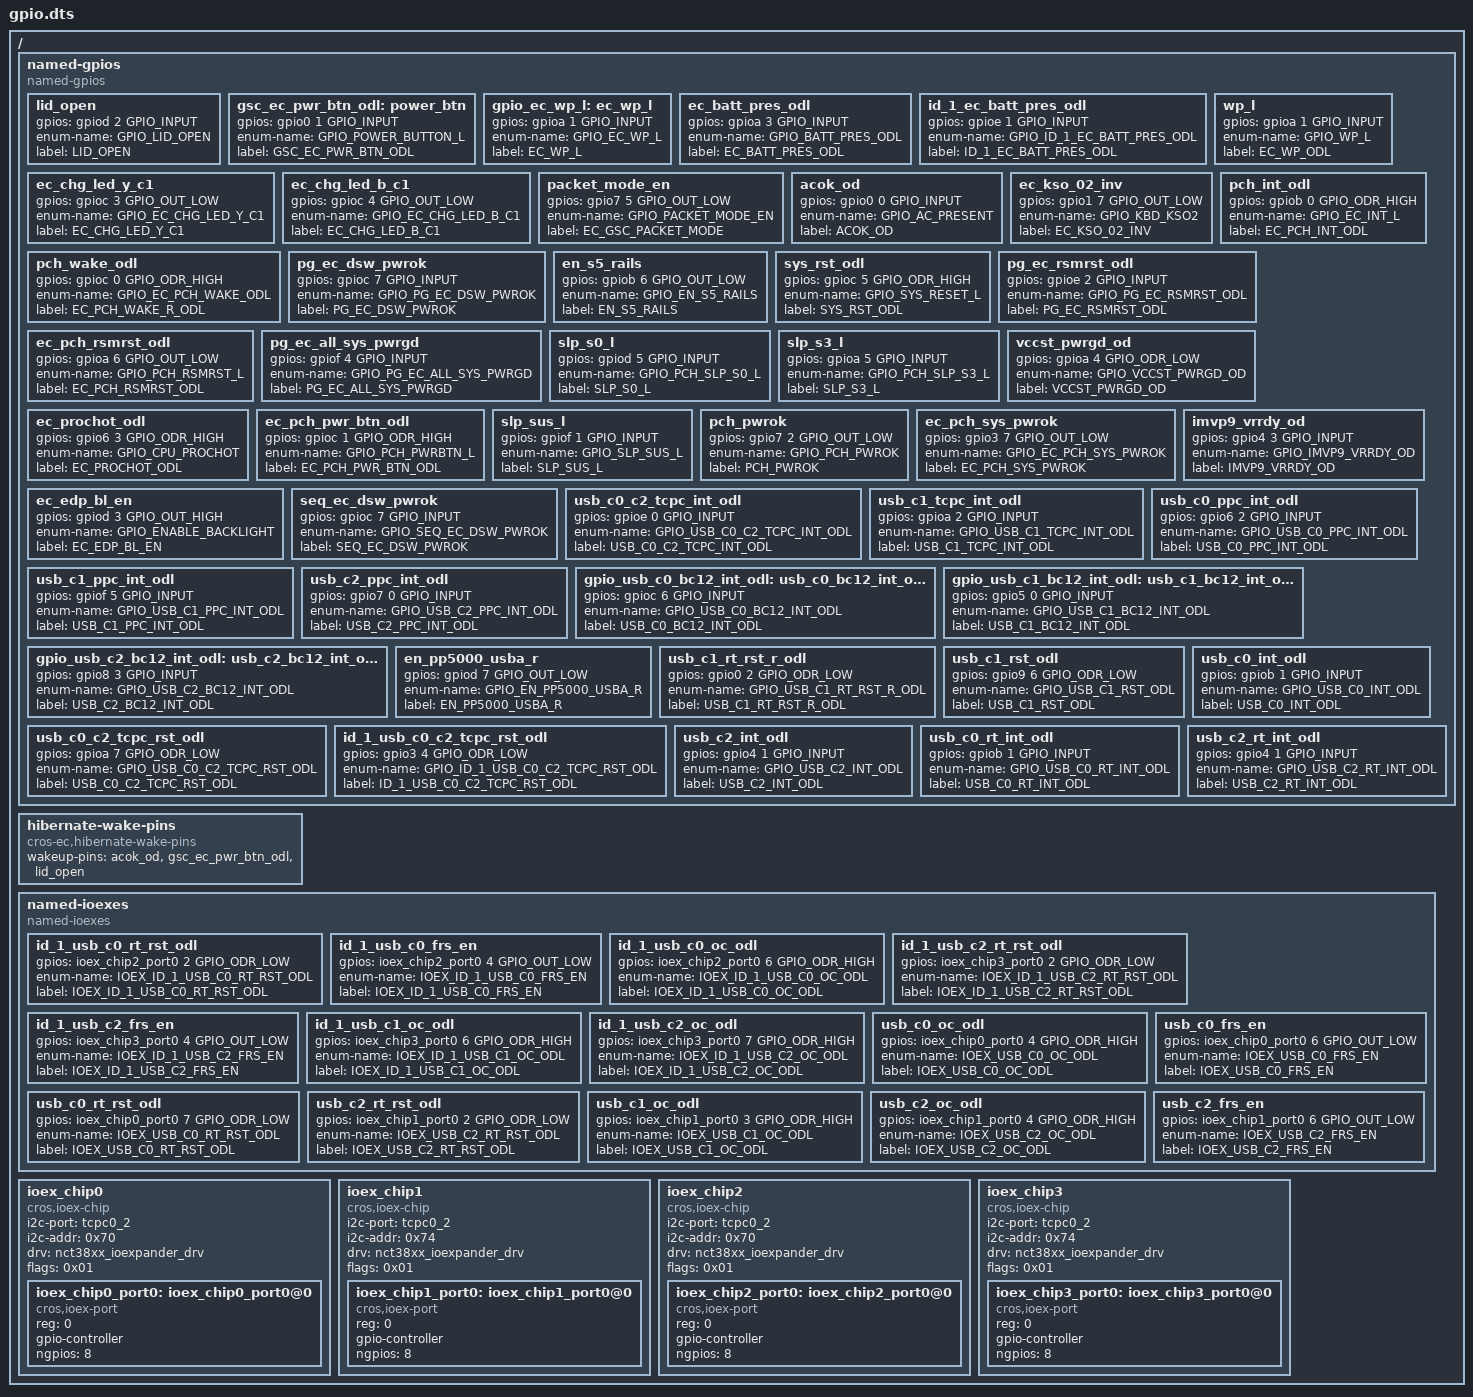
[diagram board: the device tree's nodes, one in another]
/* Copyright 2021 The Chromium OS Authors. All rights reserved.
 * Use of this source code is governed by a BSD-style license that can be
 * found in the LICENSE file.
 */

/ {
	named-gpios {
		compatible = "named-gpios";

		lid_open: lid_open {
			gpios = <&gpiod 2 GPIO_INPUT>;
			enum-name = "GPIO_LID_OPEN";
			label = "LID_OPEN";
		};

		gsc_ec_pwr_btn_odl: power_btn {
			gpios = <&gpio0 1 GPIO_INPUT>;
			enum-name = "GPIO_POWER_BUTTON_L";
			label = "GSC_EC_PWR_BTN_ODL";
		};

		gpio_ec_wp_l: ec_wp_l {
			#gpio-cells = <0>;
			gpios = <&gpioa 1 GPIO_INPUT>;
			enum-name = "GPIO_EC_WP_L";
			label = "EC_WP_L";
		};

		ec_batt_pres_odl {
			gpios = <&gpioa 3 GPIO_INPUT>;
			enum-name = "GPIO_BATT_PRES_ODL";
			label = "EC_BATT_PRES_ODL";
		};

		id_1_ec_batt_pres_odl {
			gpios = <&gpioe 1 GPIO_INPUT>;
			enum-name = "GPIO_ID_1_EC_BATT_PRES_ODL";
			label = "ID_1_EC_BATT_PRES_ODL";
		};

		wp_l {
			gpios = <&gpioa 1 GPIO_INPUT>;
			enum-name = "GPIO_WP_L";
			label = "EC_WP_ODL";
		};

		ec_chg_led_y_c1 {
			gpios = <&gpioc 3 GPIO_OUT_LOW>;
			enum-name = "GPIO_EC_CHG_LED_Y_C1";
			label = "EC_CHG_LED_Y_C1";
		};

		ec_chg_led_b_c1 {
			gpios = <&gpioc 4 GPIO_OUT_LOW>;
			enum-name = "GPIO_EC_CHG_LED_B_C1";
			label = "EC_CHG_LED_B_C1";
		};

		packet_mode_en {
			gpios = <&gpio7 5 GPIO_OUT_LOW>;
			enum-name = "GPIO_PACKET_MODE_EN";
			label = "EC_GSC_PACKET_MODE";
		};
		acok_od: acok_od {
			gpios = <&gpio0 0 GPIO_INPUT>;
			enum-name = "GPIO_AC_PRESENT";
			label = "ACOK_OD";
		};
		ec_kso_02_inv {
			gpios = <&gpio1 7 GPIO_OUT_LOW>;
			enum-name = "GPIO_KBD_KSO2";
			label = "EC_KSO_02_INV";
		};
		pch_wake_odl {
			gpios = <&gpioc 0 GPIO_ODR_HIGH>;
			enum-name = "GPIO_EC_PCH_WAKE_ODL";
			label = "EC_PCH_WAKE_R_ODL";
		};
		pch_int_odl {
			gpios = <&gpiob 0 GPIO_ODR_HIGH>;
			enum-name = "GPIO_EC_INT_L";
			label = "EC_PCH_INT_ODL";
		};
		pg_ec_dsw_pwrok {
			gpios = <&gpioc 7 GPIO_INPUT>;
			enum-name = "GPIO_PG_EC_DSW_PWROK";
			label = "PG_EC_DSW_PWROK";
		};
		en_s5_rails {
			gpios = <&gpiob 6 GPIO_OUT_LOW>;
			enum-name = "GPIO_EN_S5_RAILS";
			label = "EN_S5_RAILS";
		};
		sys_rst_odl {
			gpios = <&gpioc 5 GPIO_ODR_HIGH>;
			enum-name = "GPIO_SYS_RESET_L";
			label = "SYS_RST_ODL";
		};
		pg_ec_rsmrst_odl {
			gpios = <&gpioe 2 GPIO_INPUT>;
			enum-name = "GPIO_PG_EC_RSMRST_ODL";
			label = "PG_EC_RSMRST_ODL";
		};
		ec_pch_rsmrst_odl {
			gpios = <&gpioa 6 GPIO_OUT_LOW>;
			enum-name = "GPIO_PCH_RSMRST_L";
			label = "EC_PCH_RSMRST_ODL";
		};
		pg_ec_all_sys_pwrgd {
			gpios = <&gpiof 4 GPIO_INPUT>;
			enum-name = "GPIO_PG_EC_ALL_SYS_PWRGD";
			label = "PG_EC_ALL_SYS_PWRGD";
		};
		slp_s0_l {
			gpios = <&gpiod 5 GPIO_INPUT>;
			enum-name = "GPIO_PCH_SLP_S0_L";
			label = "SLP_S0_L";
		};
		slp_s3_l {
			gpios = <&gpioa 5 GPIO_INPUT>;
			enum-name = "GPIO_PCH_SLP_S3_L";
			label = "SLP_S3_L";
		};
		vccst_pwrgd_od {
			gpios = <&gpioa 4 GPIO_ODR_LOW>;
			enum-name = "GPIO_VCCST_PWRGD_OD";
			label = "VCCST_PWRGD_OD";
		};
		ec_prochot_odl {
			gpios = <&gpio6 3 GPIO_ODR_HIGH>;
			enum-name = "GPIO_CPU_PROCHOT";
			label = "EC_PROCHOT_ODL";
		};
		ec_pch_pwr_btn_odl {
			gpios = <&gpioc 1 GPIO_ODR_HIGH>;
			enum-name = "GPIO_PCH_PWRBTN_L";
			label = "EC_PCH_PWR_BTN_ODL";
		};
		slp_sus_l {
			gpios = <&gpiof 1 GPIO_INPUT>;
			enum-name = "GPIO_SLP_SUS_L";
			label = "SLP_SUS_L";
		};
		pch_pwrok {
			gpios = <&gpio7 2 GPIO_OUT_LOW>;
			enum-name = "GPIO_PCH_PWROK";
			label = "PCH_PWROK";
		};
		ec_pch_sys_pwrok {
			gpios = <&gpio3 7 GPIO_OUT_LOW>;
			enum-name = "GPIO_EC_PCH_SYS_PWROK";
			label = "EC_PCH_SYS_PWROK";
		};
		imvp9_vrrdy_od {
			gpios = <&gpio4 3 GPIO_INPUT>;
			enum-name = "GPIO_IMVP9_VRRDY_OD";
			label = "IMVP9_VRRDY_OD";
		};
		ec_edp_bl_en {
			gpios = <&gpiod 3 GPIO_OUT_HIGH>;
			enum-name = "GPIO_ENABLE_BACKLIGHT";
			label = "EC_EDP_BL_EN";
		};
		seq_ec_dsw_pwrok {
			gpios = <&gpioc 7 GPIO_INPUT>;
			enum-name = "GPIO_SEQ_EC_DSW_PWROK";
			label = "SEQ_EC_DSW_PWROK";
		};
		usb_c0_c2_tcpc_int_odl {
			gpios = <&gpioe 0 GPIO_INPUT>;
			enum-name = "GPIO_USB_C0_C2_TCPC_INT_ODL";
			label = "USB_C0_C2_TCPC_INT_ODL";
		};
		usb_c1_tcpc_int_odl {
			gpios = <&gpioa 2 GPIO_INPUT>;
			enum-name = "GPIO_USB_C1_TCPC_INT_ODL";
			label = "USB_C1_TCPC_INT_ODL";
		};
		usb_c0_ppc_int_odl {
			gpios = <&gpio6 2 GPIO_INPUT>;
			enum-name = "GPIO_USB_C0_PPC_INT_ODL";
			label = "USB_C0_PPC_INT_ODL";
		};
		usb_c1_ppc_int_odl {
			gpios = <&gpiof 5 GPIO_INPUT>;
			enum-name = "GPIO_USB_C1_PPC_INT_ODL";
			label = "USB_C1_PPC_INT_ODL";
		};
		usb_c2_ppc_int_odl {
			gpios = <&gpio7 0 GPIO_INPUT>;
			enum-name = "GPIO_USB_C2_PPC_INT_ODL";
			label = "USB_C2_PPC_INT_ODL";
		};
		gpio_usb_c0_bc12_int_odl: usb_c0_bc12_int_odl {
			gpios = <&gpioc 6 GPIO_INPUT>;
			enum-name = "GPIO_USB_C0_BC12_INT_ODL";
			label = "USB_C0_BC12_INT_ODL";
		};
		gpio_usb_c1_bc12_int_odl: usb_c1_bc12_int_odl {
			gpios = <&gpio5 0 GPIO_INPUT>;
			enum-name = "GPIO_USB_C1_BC12_INT_ODL";
			label = "USB_C1_BC12_INT_ODL";
		};
		gpio_usb_c2_bc12_int_odl: usb_c2_bc12_int_odl {
			gpios = <&gpio8 3 GPIO_INPUT>;
			enum-name = "GPIO_USB_C2_BC12_INT_ODL";
			label = "USB_C2_BC12_INT_ODL";
		};
		en_pp5000_usba_r {
			gpios = <&gpiod 7 GPIO_OUT_LOW>;
			enum-name = "GPIO_EN_PP5000_USBA_R";
			label = "EN_PP5000_USBA_R";
		};
		usb_c1_rt_rst_r_odl {
			gpios = <&gpio0 2 GPIO_ODR_LOW>;
			enum-name = "GPIO_USB_C1_RT_RST_R_ODL";
			label = "USB_C1_RT_RST_R_ODL";
		};
		usb_c1_rst_odl {
			gpios = <&gpio9 6 GPIO_ODR_LOW>;
			enum-name = "GPIO_USB_C1_RST_ODL";
			label = "USB_C1_RST_ODL";
		};
		usb_c0_c2_tcpc_rst_odl {
			gpios = <&gpioa 7 GPIO_ODR_LOW>;
			enum-name = "GPIO_USB_C0_C2_TCPC_RST_ODL";
			label = "USB_C0_C2_TCPC_RST_ODL";
		};
		id_1_usb_c0_c2_tcpc_rst_odl {
			gpios = <&gpio3 4 GPIO_ODR_LOW>;
			enum-name = "GPIO_ID_1_USB_C0_C2_TCPC_RST_ODL";
			label = "ID_1_USB_C0_C2_TCPC_RST_ODL";
		};
		usb_c0_int_odl {
			gpios = <&gpiob 1 GPIO_INPUT>;
			enum-name = "GPIO_USB_C0_INT_ODL";
			label = "USB_C0_INT_ODL";
		};
		usb_c2_int_odl {
			gpios = <&gpio4 1 GPIO_INPUT>;
			enum-name = "GPIO_USB_C2_INT_ODL";
			label = "USB_C2_INT_ODL";
		};
		usb_c0_rt_int_odl: usb_c0_rt_int_odl {
			#gpio-cells = <0>;
			gpios = <&gpiob 1 GPIO_INPUT>;
			enum-name = "GPIO_USB_C0_RT_INT_ODL";
			label = "USB_C0_RT_INT_ODL";
		};
		usb_c2_rt_int_odl: usb_c2_rt_int_odl {
			#gpio-cells = <0>;
			gpios = <&gpio4 1 GPIO_INPUT>;
			enum-name = "GPIO_USB_C2_RT_INT_ODL";
			label = "USB_C2_RT_INT_ODL";
		};
	};

	hibernate-wake-pins {
		compatible = "cros-ec,hibernate-wake-pins";
		wakeup-pins = <
			&acok_od
			&gsc_ec_pwr_btn_odl
			&lid_open
		>;
	};

	named-ioexes {
		compatible = "named-ioexes";

		id_1_usb_c0_rt_rst_odl {
			gpios = <&ioex_chip2_port0 2 GPIO_ODR_LOW>;
			enum-name = "IOEX_ID_1_USB_C0_RT_RST_ODL";
			label = "IOEX_ID_1_USB_C0_RT_RST_ODL";
		};
		id_1_usb_c0_frs_en {
			gpios = <&ioex_chip2_port0 4 GPIO_OUT_LOW>;
			enum-name = "IOEX_ID_1_USB_C0_FRS_EN";
			label = "IOEX_ID_1_USB_C0_FRS_EN";
		};
		id_1_usb_c0_oc_odl {
			gpios = <&ioex_chip2_port0 6 GPIO_ODR_HIGH>;
			enum-name = "IOEX_ID_1_USB_C0_OC_ODL";
			label = "IOEX_ID_1_USB_C0_OC_ODL";
		};
		id_1_usb_c2_rt_rst_odl {
			gpios = <&ioex_chip3_port0 2 GPIO_ODR_LOW>;
			enum-name = "IOEX_ID_1_USB_C2_RT_RST_ODL";
			label = "IOEX_ID_1_USB_C2_RT_RST_ODL";
		};
		id_1_usb_c2_frs_en {
			gpios = <&ioex_chip3_port0 4 GPIO_OUT_LOW>;
			enum-name = "IOEX_ID_1_USB_C2_FRS_EN";
			label = "IOEX_ID_1_USB_C2_FRS_EN";
		};
		id_1_usb_c1_oc_odl {
			gpios = <&ioex_chip3_port0 6 GPIO_ODR_HIGH>;
			enum-name = "IOEX_ID_1_USB_C1_OC_ODL";
			label = "IOEX_ID_1_USB_C1_OC_ODL";
		};
		id_1_usb_c2_oc_odl {
			gpios = <&ioex_chip3_port0 7 GPIO_ODR_HIGH>;
			enum-name = "IOEX_ID_1_USB_C2_OC_ODL";
			label = "IOEX_ID_1_USB_C2_OC_ODL";
		};
		usb_c0_oc_odl {
			gpios = <&ioex_chip0_port0 4 GPIO_ODR_HIGH>;
			enum-name = "IOEX_USB_C0_OC_ODL";
			label = "IOEX_USB_C0_OC_ODL";
		};
		usb_c0_frs_en {
			gpios = <&ioex_chip0_port0 6 GPIO_OUT_LOW>;
			enum-name = "IOEX_USB_C0_FRS_EN";
			label = "IOEX_USB_C0_FRS_EN";
		};
		usb_c0_rt_rst_odl: usb_c0_rt_rst_odl {
			#gpio-cells = <0>;
			gpios = <&ioex_chip0_port0 7 GPIO_ODR_LOW>;
			enum-name = "IOEX_USB_C0_RT_RST_ODL";
			label = "IOEX_USB_C0_RT_RST_ODL";
		};
		usb_c2_rt_rst_odl: usb_c2_rt_rst_odl {
			#gpio-cells = <0>;
			gpios = <&ioex_chip1_port0 2 GPIO_ODR_LOW>;
			enum-name = "IOEX_USB_C2_RT_RST_ODL";
			label = "IOEX_USB_C2_RT_RST_ODL";
		};
		usb_c1_oc_odl {
			gpios = <&ioex_chip1_port0 3 GPIO_ODR_HIGH>;
			enum-name = "IOEX_USB_C1_OC_ODL";
			label = "IOEX_USB_C1_OC_ODL";
		};
		usb_c2_oc_odl {
			gpios = <&ioex_chip1_port0 4 GPIO_ODR_HIGH>;
			enum-name = "IOEX_USB_C2_OC_ODL";
			label = "IOEX_USB_C2_OC_ODL";
		};
		usb_c2_frs_en {
			gpios = <&ioex_chip1_port0 6 GPIO_OUT_LOW>;
			enum-name = "IOEX_USB_C2_FRS_EN";
			label = "IOEX_USB_C2_FRS_EN";
		};
	};

	/*
	 *EC code assumes oder of ioex_chip will not change in below
	 *configuration
	 */
	/*IOEX_C0_NCT38XX*/
	ioex_chip0: ioex_chip0 {
		compatible = "cros,ioex-chip";
		i2c-port = <&tcpc0_2>;
		i2c-addr = <0x70>;
		drv = "nct38xx_ioexpander_drv";
		flags = <0x01>;
		#address-cells = <1>;
		#size-cells = <0>;
		ioex_chip0_port0: ioex_chip0_port0@0 {
			compatible = "cros,ioex-port";
			reg = <0>;
			gpio-controller;
			#gpio-cells = <2>;
			ngpios = <8>;
		};
	};

	/*IOEX_C2_NCT38XX*/
	ioex_chip1: ioex_chip1 {
		compatible = "cros,ioex-chip";
		i2c-port = <&tcpc0_2>;
		i2c-addr = <0x74>;
		drv = "nct38xx_ioexpander_drv";
		flags = <0x01>;
		#address-cells = <1>;
		#size-cells = <0>;
		ioex_chip1_port0: ioex_chip1_port0@0 {
			compatible = "cros,ioex-port";
			reg = <0>;
			gpio-controller;
			#gpio-cells = <2>;
			ngpios = <8>;
		};
	};

	/*IOEX_ID_1_C0_NCT38XX*/
	ioex_chip2: ioex_chip2 {
		compatible = "cros,ioex-chip";
		i2c-port = <&tcpc0_2>;
		i2c-addr = <0x70>;
		drv = "nct38xx_ioexpander_drv";
		flags = <0x01>;
		#address-cells = <1>;
		#size-cells = <0>;
		ioex_chip2_port0: ioex_chip2_port0@0 {
			compatible = "cros,ioex-port";
			reg = <0>;
			gpio-controller;
			#gpio-cells = <2>;
			ngpios = <8>;
		};
	};

	/*IOEX_ID_1_C2_NCT38XX*/
	ioex_chip3: ioex_chip3 {
		compatible = "cros,ioex-chip";
		i2c-port = <&tcpc0_2>;
		i2c-addr = <0x74>;
		drv = "nct38xx_ioexpander_drv";
		flags = <0x01>;
		#address-cells = <1>;
		#size-cells = <0>;
		ioex_chip3_port0: ioex_chip3_port0@0 {
			compatible = "cros,ioex-port";
			reg = <0>;
			gpio-controller;
			#gpio-cells = <2>;
			ngpios = <8>;
		};
	};
};
